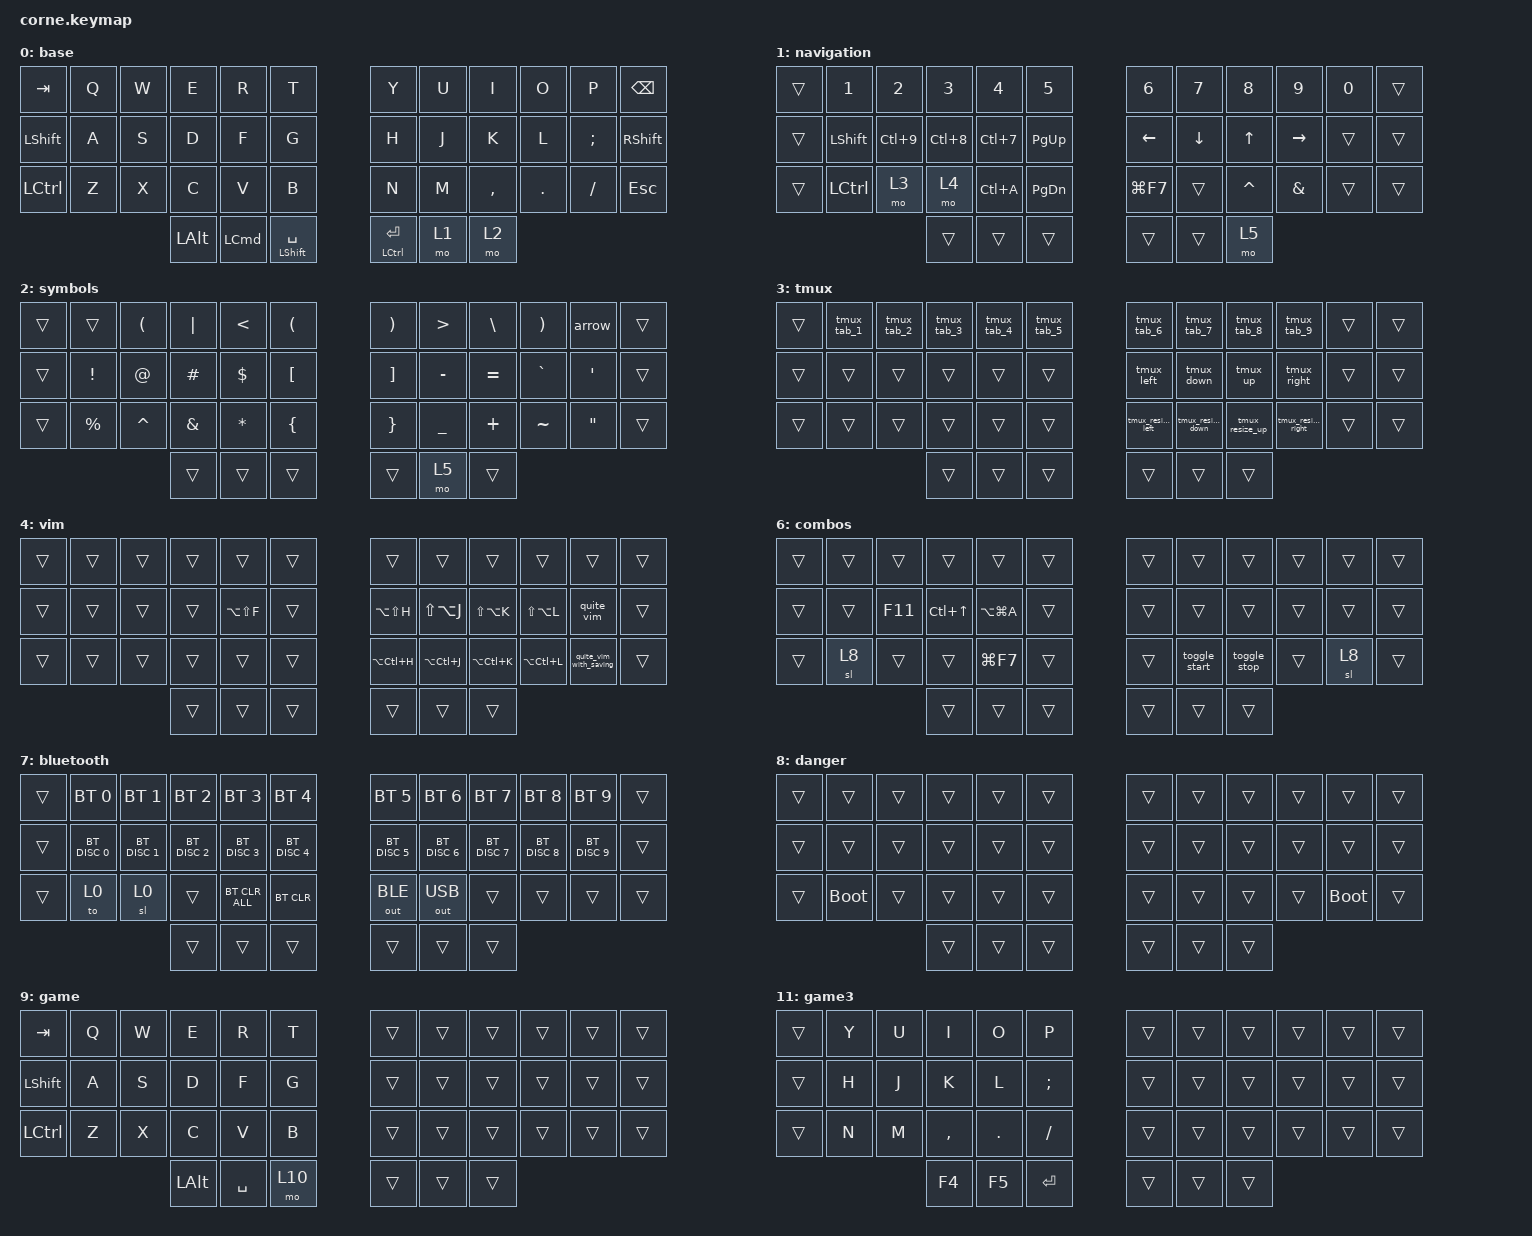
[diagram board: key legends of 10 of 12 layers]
#include <dt-bindings/zmk/mouse.h>
#include <behaviors.dtsi>
#include <dt-bindings/zmk/bt.h>
#include <dt-bindings/zmk/keys.h>
#include <dt-bindings/zmk/outputs.h>

#define U_TAPPING_TERM 200

&sk { quick-release; };

/ {
    combos {
        compatible = "zmk,combos";

        tab {
            bindings = <&kp TAB>;
            key-positions = <15 16>;
        };

        backspace {
            bindings = <&kp BACKSPACE>;
            key-positions = <19 20>;
        };

        delete {
            bindings = <&kp DELETE>;
            key-positions = <20 21>;
        };

        meta {
            bindings = <&hold_sticky_key LS(LA(LC(LEFT_GUI))) LS(LA(LC(LEFT_GUI)))>;
            key-positions = <13 14 15 16>;
            layers = <0 1>;
        };

        left_gui_space {
            bindings = <&kp LG(SPACE)>;
            key-positions = <37 38>;
        };

        to_base_layer {
            bindings = <&to 0>;
            key-positions = <28 29>;
        };

        layer_5 {
            bindings = <&mo 5>;
            key-positions = <37 40>;
        };
    };

    behaviors {
        ctrl_alt_dance: ctrl_alt_dance {
            compatible = "zmk,behavior-tap-dance";
            label = "CTRL_ALT_DANCE";
            #binding-cells = <0>;
            tapping-term-ms = <200>;
            bindings = <&kp LCTRL>, <&kp LEFT_ALT>;
        };

        hold_tap: hold_tap {
            compatible = "zmk,behavior-hold-tap";
            label = "HOLD_TAP";
            bindings = <&kp>, <&kp>;

            #binding-cells = <2>;
            tapping-term-ms = <200>;
            flavor = "tap-preferred";
            quick-tap-ms = <100>;
        };

        layer_tap: layer_tap {
            compatible = "zmk,behavior-hold-tap";
            label = "LAYER_TAP";
            #binding-cells = <2>;
            tapping-term-ms = <200>;
            flavor = "balanced";
            bindings = <&mo>, <&kp>;
        };

        speclayers: speclayers {
            compatible = "zmk,behavior-tap-dance";
            label = "SPECLAYERS";
            #binding-cells = <0>;
            bindings = <&sl 5>, <&sl 6>;
        };

        hold_sticky_key: hold_sticky_key {
            compatible = "zmk,behavior-hold-tap";
            label = "HOLD_STICKY_KEY";
            bindings = <&kp>, <&sk>;

            #binding-cells = <2>;
            tapping-term-ms = <200>;
            flavor = "tap-preferred";
            quick-tap-ms = <100>;
        };

        hold_spec_layer: hold_spec_layer {
            compatible = "zmk,behavior-hold-tap";
            label = "HOLD_SPEC_LAYER";
            bindings = <&kp>, <&speclayers>;

            #binding-cells = <2>;
            tapping-term-ms = <200>;
            quick-tap-ms = <100>;
            flavor = "tap-preferred";
        };

        left_shift_caps: left_shift_caps {
            compatible = "zmk,behavior-tap-dance";
            label = "LEFT_SHIFT_CAPS";
            #binding-cells = <0>;
            bindings = <&hold_sticky_key LEFT_SHIFT LEFT_SHIFT>, <&caps_word>;
        };

        right_shift_caps: right_shift_caps {
            compatible = "zmk,behavior-tap-dance";
            label = "RIGHT_SHIFT_CAPS";
            #binding-cells = <0>;
            bindings = <&hold_sticky_key RIGHT_SHIFT RIGHT_SHIFT>, <&caps_word>;
        };

        hold_sticky_layer: hold_sticky_layer {
            compatible = "zmk,behavior-hold-tap";
            label = "HOLD_STICKY_LAYER";
            bindings = <&kp>, <&sl>;

            #binding-cells = <2>;
            tapping-term-ms = <200>;
            flavor = "balanced";
        };

        hold_or_sticky_layer: hold_or_sticky_layer {
            compatible = "zmk,behavior-hold-tap";
            label = "HOLD_OR_STICKY_LAYER";
            bindings = <&mo>, <&sl>;

            #binding-cells = <2>;
            tapping-term-ms = <100>;
            flavor = "tap-preferred";
        };

        hold_to_layer: hold_to_layer {
            compatible = "zmk,behavior-hold-tap";
            label = "HOLD_TO_LAYER";
            bindings = <&kp>, <&to>;

            #binding-cells = <2>;
            flavor = "balanced";
            tapping-term-ms = <200>;
        };
    };

    macros {
        toggle_start: toggle_start {
            compatible = "zmk,behavior-macro";
            #binding-cells = <0>;
            bindings =
                <&macro_tap>,
                <&kp LS(LA(LC(LG(T))))>,
                <&macro_wait_time 300>,
                <&macro_tap>,
                <&kp RG(O) &kp LG(TAB)>;

            label = "TOGGLE_START";
            wait-ms = <1000>;
            tap-ms = <10>;
        };

        toggle_stop: toggle_stop {
            compatible = "zmk,behavior-macro";
            #binding-cells = <0>;
            bindings =
                <&macro_tap>,
                <&kp LS(LA(LC(LG(T))))>,
                <&macro_wait_time 300>,
                <&macro_tap>,
                <&kp RG(S) &kp LG(TAB)>;

            label = "TOGGLE_STOP";
            wait-ms = <1000>;
            tap-ms = <10>;
        };

        tripple_escape: tripple_escape {
            compatible = "zmk,behavior-macro";
            #binding-cells = <0>;
            bindings = <&macro_tap>, <&kp ESCAPE &kp ESCAPE &kp ESCAPE>;

            label = "TRIPPLE_ESCAPE";
        };

        quite_vim: quite_vim {
            compatible = "zmk,behavior-macro";
            #binding-cells = <0>;
            bindings = <&macro_tap>, <&kp COLON &kp Q &kp A &kp ENTER>;

            label = "QUITE_VIM";
        };

        arrow: arrow {
            compatible = "zmk,behavior-macro";
            #binding-cells = <0>;
            bindings = <&kp EQUAL &kp GREATER_THAN>;
            label = "ARROW";
        };

        task: task {
            compatible = "zmk,behavior-macro";
            #binding-cells = <0>;
            bindings = <&kp MINUS &kp SPACE &kp LBKT &kp SPACE &kp RIGHT_BRACKET &kp SPACE>;
            label = "TASK";
        };

        double_click: double_click {
            compatible = "zmk,behavior-macro";
            #binding-cells = <0>;
            bindings = <&mkp MB1 &mkp MB1>;
            label = "DOUBLE_CLICK";
            wait-ms = <50>;
        };

        tmux_left: tmux_left {
            compatible = "zmk,behavior-macro";
            #binding-cells = <0>;
            bindings = <&kp LC(A) &kp LEFT>;
            label = "TMUX_LEFT";
        };

        tmux_down: tmux_down {
            compatible = "zmk,behavior-macro";
            #binding-cells = <0>;
            bindings = <&kp LC(A) &kp DOWN>;
            label = "TMUX_DOWN";
        };

        tmux_up: tmux_up {
            compatible = "zmk,behavior-macro";
            #binding-cells = <0>;
            bindings = <&kp LC(A) &kp UP_ARROW>;
            label = "TMUX_UP";
        };

        tmux_right: tmux_right {
            compatible = "zmk,behavior-macro";
            #binding-cells = <0>;
            bindings = <&kp LC(A) &kp RIGHT>;
            label = "TMUX_RIGHT";
        };

        tmux_resize_left: tmux_resize_left {
            compatible = "zmk,behavior-macro";
            #binding-cells = <0>;
            bindings = <&kp LC(A) &kp LC(LEFT)>;
            label = "TMUX_RESIZE_LEFT";
        };

        tmux_resize_down: tmux_resize_down {
            compatible = "zmk,behavior-macro";
            #binding-cells = <0>;
            bindings = <&kp LC(A) &kp LC(DOWN)>;
            label = "TMUX_RESIZE_DOWN";
        };

        tmux_resize_up: tmux_resize_up {
            compatible = "zmk,behavior-macro";
            #binding-cells = <0>;
            bindings = <&kp LC(A) &kp LC(UP_ARROW)>;
            label = "TMUX_RESIZE_UP";
        };

        tmux_resize_right: tmux_resize_right {
            compatible = "zmk,behavior-macro";
            #binding-cells = <0>;
            bindings = <&kp LC(A) &kp LC(RIGHT)>;
            label = "TMUX_RESIZE_RIGHT";
        };

        tmux_tab_1: tmux_tab_1 {
            compatible = "zmk,behavior-macro";
            #binding-cells = <0>;
            bindings = <&kp LC(A) &kp NUMBER_1>;
            label = "TMUX_TAB_1";
        };

        tmux_tab_2: tmux_tab_2 {
            compatible = "zmk,behavior-macro";
            #binding-cells = <0>;
            bindings = <&kp LC(A) &kp NUMBER_2>;
            label = "TMUX_TAB_2";
        };

        tmux_tab_3: tmux_tab_3 {
            compatible = "zmk,behavior-macro";
            #binding-cells = <0>;
            bindings = <&kp LC(A) &kp NUMBER_3>;
            label = "TMUX_TAB_3";
        };

        tmux_tab_4: tmux_tab_4 {
            compatible = "zmk,behavior-macro";
            #binding-cells = <0>;
            bindings = <&kp LC(A) &kp NUMBER_4>;
            label = "TMUX_TAB_4";
        };

        tmux_tab_5: tmux_tab_5 {
            compatible = "zmk,behavior-macro";
            #binding-cells = <0>;
            bindings = <&kp LC(A) &kp N5>;
            label = "TMUX_TAB_5";
        };

        tmux_tab_6: tmux_tab_6 {
            compatible = "zmk,behavior-macro";
            #binding-cells = <0>;
            bindings = <&kp LC(A) &kp NUMBER_6>;
            label = "TMUX_TAB_6";
        };

        tmux_tab_7: tmux_tab_7 {
            compatible = "zmk,behavior-macro";
            #binding-cells = <0>;
            bindings = <&kp LC(A) &kp N7>;
            label = "TMUX_TAB_7";
        };

        tmux_tab_8: tmux_tab_8 {
            compatible = "zmk,behavior-macro";
            #binding-cells = <0>;
            bindings = <&kp LC(A) &kp N8>;
            label = "TMUX_TAB_8";
        };

        tmux_tab_9: tmux_tab_9 {
            compatible = "zmk,behavior-macro";
            #binding-cells = <0>;
            bindings = <&kp LC(A) &kp N9>;
            label = "TMUX_TAB_9";
        };

        quite_vim_with_saving: quite_vim_with_saving {
            compatible = "zmk,behavior-macro";
            #binding-cells = <0>;
            bindings = <&macro_tap>, <&kp COLON &kp W &kp Q &kp A &kp ENTER>;

            label = "QUITE_VIM_WITH_SAVING";
        };

        cmd_tab: cmd_tab {
            compatible = "zmk,behavior-mod-morph";
            label = "CMD_TAB";
            bindings = <&layer_tap 1 ESCAPE>, <&kp TAB>;

            #binding-cells = <0>;
            mods = <(MOD_LGUI|MOD_RGUI|MOD_LALT|MOD_RALT)>;
            keep-mods = <(MOD_LALT|MOD_LGUI|MOD_RALT|MOD_RGUI)>;
        };

        layer_mkp: layer_mkp {
            compatible = "zmk,behavior-hold-tap";
            label = "LAYER_MKP";
            bindings = <&mo>, <&mkp>;

            #binding-cells = <2>;
            tapping-term-ms = <100>;
        };
    };

    keymap {
        compatible = "zmk,keymap";

        base {
            bindings = <
&kp TAB           &kp Q  &kp W  &kp E         &kp R     &kp T                         &kp Y                         &kp U  &kp I      &kp O       &kp P          &kp BACKSPACE
&kp LEFT_SHIFT    &kp A  &kp S  &kp D         &kp F     &kp G                         &kp H                         &kp J  &kp K      &kp L       &kp SEMICOLON  &kp RIGHT_SHIFT
&kp LEFT_CONTROL  &kp Z  &kp X  &kp C         &kp V     &kp B                         &kp N                         &kp M  &kp COMMA  &kp PERIOD  &kp SLASH      &kp ESCAPE
                                &kp LEFT_ALT  &kp LCMD  &hold_tap LEFT_SHIFT SPACE    &hold_tap LEFT_CONTROL ENTER  &mo 1  &mo 2
            >;
        };

        navigation {
            bindings = <
&trans  &kp N1          &kp N2      &kp N3      &kp N4      &kp N5           &kp N6      &kp N7    &kp N8     &kp N9         &kp N0  &trans
&trans  &kp LEFT_SHIFT  &kp LC(N9)  &kp LC(N8)  &kp LC(N7)  &kp PG_UP        &kp LEFT    &kp DOWN  &kp UP     &kp RIGHT      &trans  &trans
&trans  &kp LCTRL       &mo 3       &mo 4       &kp LC(A)   &kp PAGE_DOWN    &kp LG(F7)  &trans    &kp CARET  &kp AMPERSAND  &trans  &trans
                                    &trans      &trans      &trans           &trans      &trans    &mo 5
            >;
        };

        symbols {
            bindings = <
&trans  &trans           &kp LEFT_PARENTHESIS  &kp PIPE       &kp LESS_THAN  &kp LEFT_PARENTHESIS    &kp RIGHT_PARENTHESIS  &kp GREATER_THAN  &kp BACKSLASH  &kp RIGHT_PARENTHESIS  &arrow             &trans
&trans  &kp EXCLAMATION  &kp AT_SIGN           &kp HASH       &kp DOLLAR     &kp LEFT_BRACKET        &kp RIGHT_BRACKET      &kp MINUS         &kp EQUAL      &kp GRAVE              &kp SQT            &trans
&trans  &kp PERCENT      &kp CARET             &kp AMPERSAND  &kp ASTERISK   &kp LEFT_BRACE          &kp RIGHT_BRACE        &kp UNDERSCORE    &kp PLUS       &kp TILDE              &kp DOUBLE_QUOTES  &trans
                                               &trans         &trans         &trans                  &trans                 &mo 5             &trans
            >;
        };

        tmux {
            bindings = <
&trans  &tmux_tab_1  &tmux_tab_2  &tmux_tab_3  &tmux_tab_4  &tmux_tab_5    &tmux_tab_6        &tmux_tab_7        &tmux_tab_8      &tmux_tab_9         &trans  &trans
&trans  &trans       &trans       &trans       &trans       &trans         &tmux_left         &tmux_down         &tmux_up         &tmux_right         &trans  &trans
&trans  &trans       &trans       &trans       &trans       &trans         &tmux_resize_left  &tmux_resize_down  &tmux_resize_up  &tmux_resize_right  &trans  &trans
                                  &trans       &trans       &trans         &trans             &trans             &trans
            >;
        };

        vim {
            bindings = <
&trans  &trans  &trans  &trans  &trans         &trans    &trans         &trans         &trans         &trans         &trans                  &trans
&trans  &trans  &trans  &trans  &kp LA(LS(F))  &trans    &kp LA(LS(H))  &kp LS(LA(J))  &kp LS(LA(K))  &kp LS(LA(L))  &quite_vim              &trans
&trans  &trans  &trans  &trans  &trans         &trans    &kp LA(LC(H))  &kp LA(LC(J))  &kp LA(LC(K))  &kp LA(LC(L))  &quite_vim_with_saving  &trans
                        &trans  &trans         &trans    &trans         &trans         &trans
            >;
        };

        functions {
            bindings = <
&trans  &kp F1                 &kp F2                 &kp F3                 &kp F4                 &kp F5                   &kp F6          &kp F7            &kp F8           &kp F9   &kp F10  &trans
&trans  &kp LS(LA(LC(LG(A))))  &kp LS(LA(LC(LG(S))))  &kp LC(LA(LS(LG(D))))  &kp LS(LA(LC(LG(F))))  &kp LS(LC(LG(LA(G))))    &kp C_VOL_DN    &kp C_MUTE        &kp C_VOLUME_UP  &kp F11  &kp F12  &trans
&trans  &kp LS(LA(LC(LG(Z))))  &kp LS(LC(LA(LG(X))))  &kp LS(LA(LC(LG(C))))  &kp LS(LA(LC(LG(V))))  &kp LS(LA(LC(LG(B))))    &kp C_PREVIOUS  &kp C_PLAY_PAUSE  &kp C_NEXT       &sl 7    &to 9    &trans
                                                      &sl 6                  &trans                 &trans                   &trans          &trans            &trans
            >;
        };

        combos {
            bindings = <
&trans  &trans  &trans   &trans            &trans         &trans    &trans  &trans         &trans        &trans  &trans  &trans
&trans  &trans  &kp F11  &kp LC(UP_ARROW)  &kp LA(LG(A))  &trans    &trans  &trans         &trans        &trans  &trans  &trans
&trans  &sl 8   &trans   &trans            &kp LG(F7)     &trans    &trans  &toggle_start  &toggle_stop  &trans  &sl 8   &trans
                         &trans            &trans         &trans    &trans  &trans         &trans
            >;
        };

        bluetooth {
            bindings = <
&trans  &bt BT_SEL 0   &bt BT_SEL 1   &bt BT_SEL 2   &bt BT_SEL 3    &bt BT_SEL 4     &bt BT_SEL 5   &bt BT_SEL 6   &bt BT_SEL 7   &bt BT_SEL 8   &bt BT_SEL 9   &trans
&trans  &bt BT_DISC 0  &bt BT_DISC 1  &bt BT_DISC 2  &bt BT_DISC 3   &bt BT_DISC 4    &bt BT_DISC 5  &bt BT_DISC 6  &bt BT_DISC 7  &bt BT_DISC 8  &bt BT_DISC 9  &trans
&trans  &to 0          &sl 0          &trans         &bt BT_CLR_ALL  &bt BT_CLR       &out OUT_BLE   &out OUT_USB   &trans         &trans         &trans         &trans
                                      &trans         &trans          &trans           &trans         &trans         &trans
            >;
        };

        danger {
            bindings = <
&trans  &trans       &trans  &trans  &trans  &trans    &trans  &trans  &trans  &trans  &trans       &trans
&trans  &trans       &trans  &trans  &trans  &trans    &trans  &trans  &trans  &trans  &trans       &trans
&trans  &bootloader  &trans  &trans  &trans  &trans    &trans  &trans  &trans  &trans  &bootloader  &trans
                             &trans  &trans  &trans    &trans  &trans  &trans
            >;
        };

        game {
            bindings = <
&kp TAB    &kp Q  &kp W  &kp E     &kp R      &kp T     &trans  &trans  &trans  &trans  &trans  &trans
&kp LSHFT  &kp A  &kp S  &kp D     &kp F      &kp G     &trans  &trans  &trans  &trans  &trans  &trans
&kp LCTRL  &kp Z  &kp X  &kp C     &kp V      &kp B     &trans  &trans  &trans  &trans  &trans  &trans
                         &kp LALT  &kp SPACE  &mo 10    &trans  &trans  &trans
            >;
        };

        game2 {
            bindings = <
&kp ESC  &kp N1  &kp N2  &kp N3  &kp Y   &trans    &trans  &trans  &trans  &trans  &trans     &kp LSHFT
&kp N4   &kp N5  &kp N6  &kp H   &trans  &trans    &trans  &trans  &trans  &trans  &kp LCTRL  &kp N7
&kp N8   &kp N9  &kp N   &trans  &trans  &trans    &trans  &trans  &trans  &trans  &trans     &trans
                         &trans  &trans  &trans
            >;
        };

        game3 {
            bindings = <
&trans  &kp Y  &kp U  &kp I      &kp O    &kp P        &trans  &trans  &trans  &trans  &trans  &trans
&trans  &kp H  &kp J  &kp K      &kp L    &kp SEMI     &trans  &trans  &trans  &trans  &trans  &trans
&trans  &kp N  &kp M  &kp COMMA  &kp DOT  &kp FSLH     &trans  &trans  &trans  &trans  &trans  &trans
                      &kp F4     &kp F5   &kp ENTER    &trans  &trans  &trans
            >;
        };
    };
};

